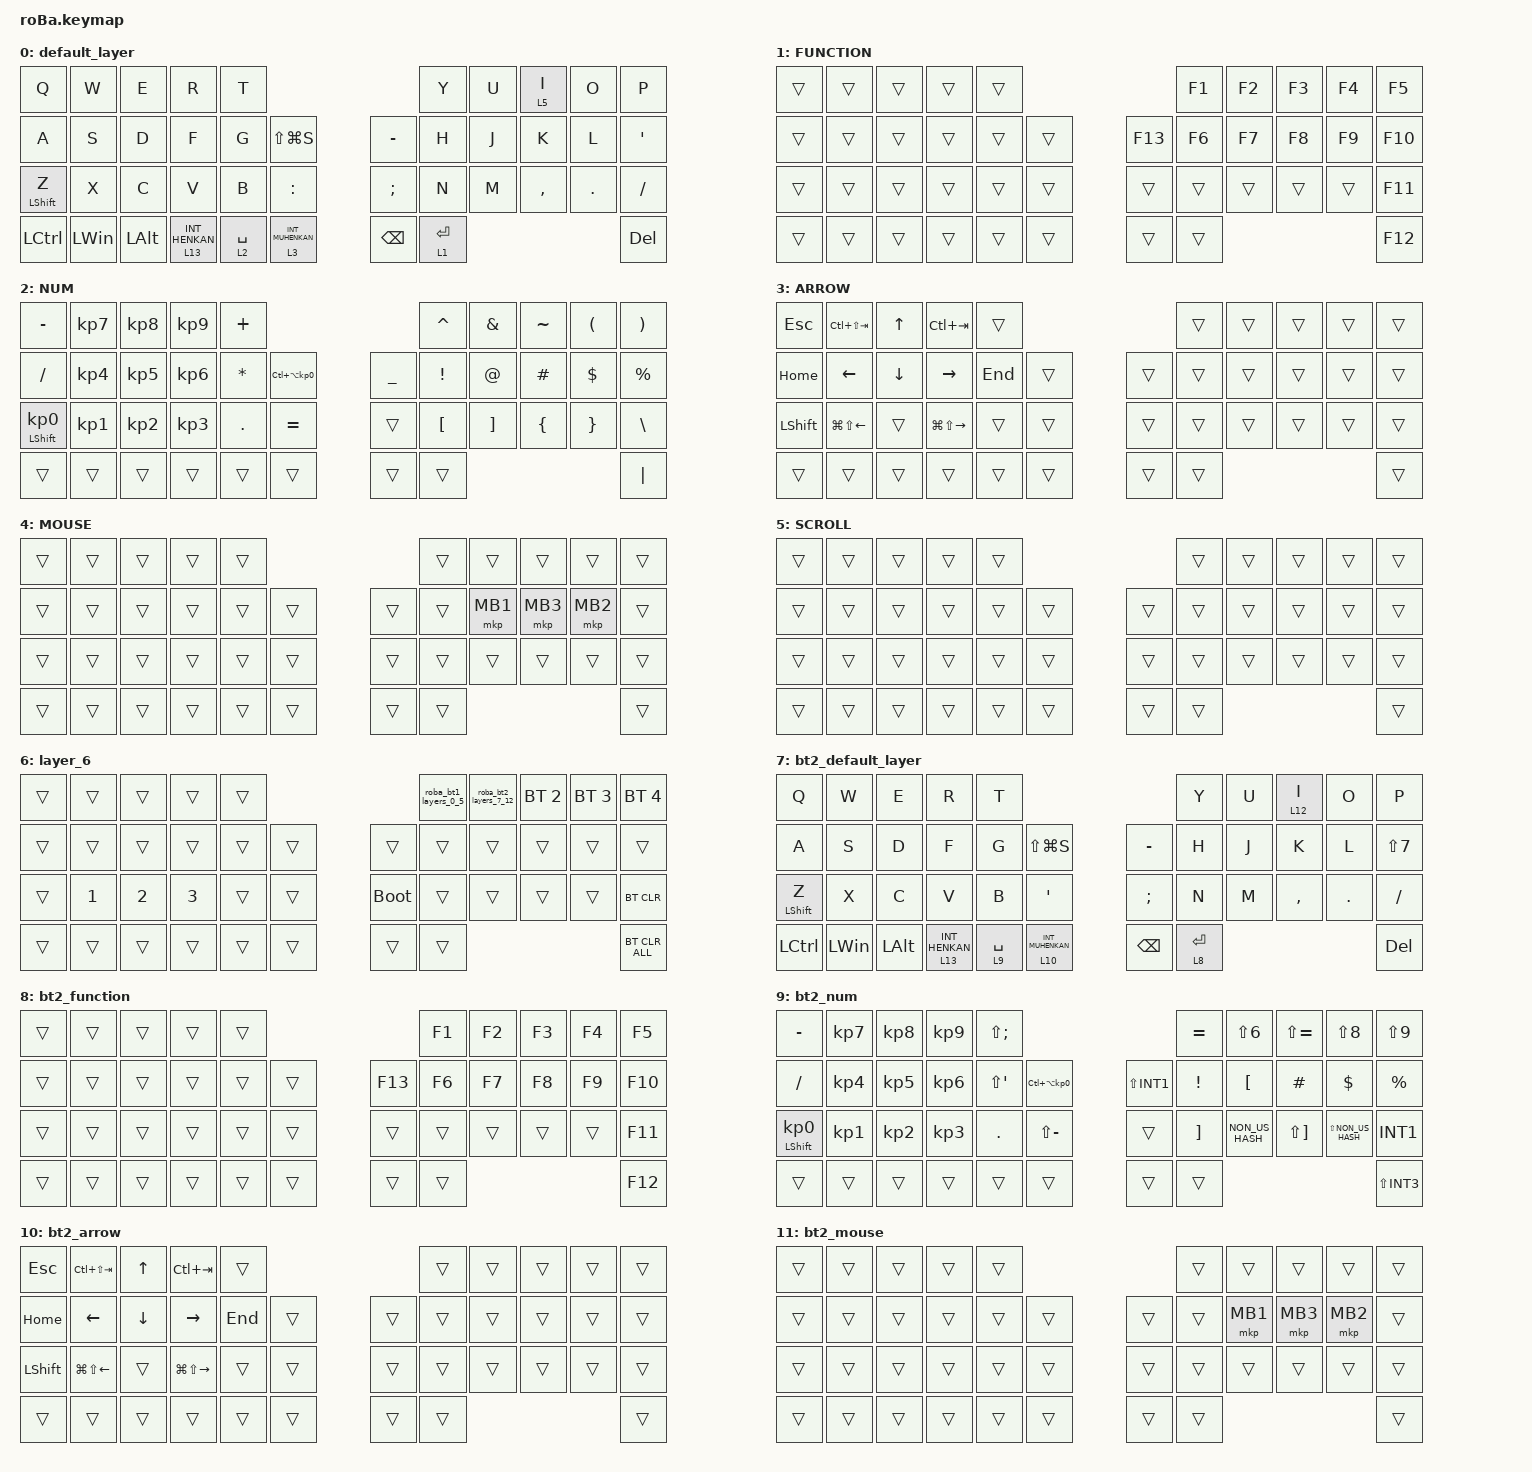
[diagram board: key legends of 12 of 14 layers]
#define ZMK_POINTING_DEFAULT_SCRL_VAL 80

#include <behaviors.dtsi>
#include <dt-bindings/zmk/bt.h>
#include <dt-bindings/zmk/keys.h>
#include <dt-bindings/zmk/pointing.h>

&mt {
    flavor = "balanced";
    quick-tap-ms = <0>;
};

&trackball {
    automouse-layer = <11>;
    scroll-layers = <12>;

    // arrows {
    //     layers = <3>;
    //     bindings =
    //         <&kp RIGHT_ARROW>,
    //         <&kp LEFT_ARROW>,
    //         <&kp UP_ARROW>,
    //         <&kp DOWN_ARROW>;

    //     tick = <10>;
    //     wait-ms = <5>;
    //     tap-ms = <5>;
    // };
};

/ {
    combos {
        compatible = "zmk,combos";

        tab {
            bindings = <&kp TAB>;
            key-positions = <11 12>;
        };

        shift_tab {
            bindings = <&kp LS(TAB)>;
            key-positions = <12 13>;
        };

        muhennkann {
            bindings = <&to_layer_0 INT_MUHENKAN>;
            key-positions = <11 10>;
        };

        double_quotation {
            bindings = <&kp DOUBLE_QUOTES>;
            key-positions = <20 21>;
        };

        eq {
            bindings = <&kp EQUAL>;
            key-positions = <24 25>;
        };
    };

    macros {
        roba_bt1_layers_0_5: roba_bt1_layers_0_5 {
            compatible = "zmk,behavior-macro";
            #binding-cells = <0>;
            display-name = "BT1 Layer Set 0";
            bindings = <&macro_tap &bt BT_SEL 0>, <&macro_tap &to 0>;
        };

        roba_bt2_layers_7_12: roba_bt2_layers_7_12 {
            compatible = "zmk,behavior-macro";
            #binding-cells = <0>;
            display-name = "BT2 Layer Set 7";
            bindings = <&macro_tap &bt BT_SEL 1>, <&macro_tap &to 7>;
        };

        to_layer_0: to_layer_0 {
            compatible = "zmk,behavior-macro-one-param";
            #binding-cells = <1>;
            bindings = <&to 0 &macro_param_1to1 &kp MACRO_PLACEHOLDER>;
            label = "TO_LAYER_0";
        };

        to_layer_7: to_layer_7 {
            compatible = "zmk,behavior-macro-one-param";
            #binding-cells = <1>;
            bindings = <&to 7 &macro_param_1to1 &kp MACRO_PLACEHOLDER>;
            label = "TO_LAYER_7";
        };
    };

    behaviors {
        encoder_msc_down_up: encoder_msc_down_up {
            compatible = "zmk,behavior-sensor-rotate";
            label = "ENCODER_MSC_DOWN_UP";
            #sensor-binding-cells = <0>;
            bindings = <&msc SCRL_DOWN>, <&msc SCRL_UP>;
            tap-ms = <20>;
        };

        lt_to_layer_0: lt_to_layer_0 {
            compatible = "zmk,behavior-hold-tap";
            label = "LAYER_TAP_TO_0";
            bindings = <&mo>, <&to_layer_0>;

            #binding-cells = <2>;
            tapping-term-ms = <200>;
        };

        lt_to_layer_7: lt_to_layer_7 {
            compatible = "zmk,behavior-hold-tap";
            label = "LAYER_TAP_TO_7";
            bindings = <&mo>, <&to_layer_7>;

            #binding-cells = <2>;
            tapping-term-ms = <200>;
        };
    };

    keymap {
        compatible = "zmk,keymap";

        default_layer {
            bindings = <
&kp Q             &kp W         &kp E         &kp R                        &kp T                                                          &kp Y        &kp U  &lt 5 I    &kp O    &kp P
&kp A             &kp S         &kp D         &kp F                        &kp G        &kp LS(LG(S))                      &kp MINUS      &kp H        &kp J  &kp K      &kp L    &kp SQT
&mt LEFT_SHIFT Z  &kp X         &kp C         &kp V                        &kp B        &kp COLON                          &kp SEMICOLON  &kp N        &kp M  &kp COMMA  &kp DOT  &kp SLASH
&kp LCTRL         &kp LEFT_WIN  &kp LEFT_ALT  &lt_to_layer_0 13 INT_HENKAN  &lt 2 SPACE  &lt_to_layer_0 3 INT_MUHENKAN      &kp BACKSPACE  &lt 1 ENTER                             &kp DEL
            >;

            sensor-bindings = <&encoder_msc_down_up>;
        };

        FUNCTION {
            bindings = <
&trans  &trans  &trans  &trans  &trans                       &kp F1  &kp F2  &kp F3  &kp F4  &kp F5
&trans  &trans  &trans  &trans  &trans  &trans      &kp F13  &kp F6  &kp F7  &kp F8  &kp F9  &kp F10
&trans  &trans  &trans  &trans  &trans  &trans      &trans   &trans  &trans  &trans  &trans  &kp F11
&trans  &trans  &trans  &trans  &trans  &trans      &trans   &trans                          &kp F12
            >;
        };

        NUM {
            bindings = <
&kp MINUS                   &kp KP_NUMBER_7  &kp KP_NUMBER_8  &kp KP_NUMBER_9  &kp PLUS                                                   &kp CARET         &kp AMPERSAND      &kp TILDE       &kp LEFT_PARENTHESIS  &kp RIGHT_PARENTHESIS
&kp SLASH                   &kp KP_NUMBER_4  &kp KP_NUMBER_5  &kp KP_NUMBER_6  &kp ASTERISK  &kp LC(LA(KP_NUMBER_0))      &kp UNDERSCORE  &kp EXCLAMATION   &kp AT_SIGN        &kp HASH        &kp DOLLAR            &kp PERCENT
&mt LEFT_SHIFT KP_NUMBER_0  &kp KP_NUMBER_1  &kp KP_NUMBER_2  &kp KP_NUMBER_3  &kp PERIOD    &kp EQUAL                    &trans          &kp LEFT_BRACKET  &kp RIGHT_BRACKET  &kp LEFT_BRACE  &kp RIGHT_BRACE       &kp BACKSLASH
&trans                      &trans           &trans           &trans           &trans        &trans                       &trans          &trans                                                                     &kp PIPE
            >;
        };

        ARROW {
            bindings = <
&kp ESCAPE      &kp LC(LS(TAB))         &kp UP_ARROW    &kp LC(TAB)              &trans                       &trans  &trans  &trans  &trans  &trans
&kp HOME        &kp LEFT_ARROW          &kp DOWN_ARROW  &kp RIGHT_ARROW          &kp END  &trans      &trans  &trans  &trans  &trans  &trans  &trans
&kp LEFT_SHIFT  &kp LG(LS(LEFT_ARROW))  &trans          &kp LG(LS(RIGHT_ARROW))  &trans   &trans      &trans  &trans  &trans  &trans  &trans  &trans
&trans          &trans                  &trans          &trans                   &trans   &trans      &trans  &trans                          &trans
            >;

            sensor-bindings = <&inc_dec_kp LC(PAGE_UP) LC(PAGE_DOWN)>;
        };

        MOUSE {
            bindings = <
&trans  &trans  &trans  &trans  &trans                      &trans  &trans    &trans    &trans    &trans
&trans  &trans  &trans  &trans  &trans  &trans      &trans  &trans  &mkp MB1  &mkp MB3  &mkp MB2  &trans
&trans  &trans  &trans  &trans  &trans  &trans      &trans  &trans  &trans    &trans    &trans    &trans
&trans  &trans  &trans  &trans  &trans  &trans      &trans  &trans                                &trans
            >;
        };

        SCROLL {
            bindings = <
&trans  &trans  &trans  &trans  &trans                      &trans  &trans  &trans  &trans  &trans
&trans  &trans  &trans  &trans  &trans  &trans      &trans  &trans  &trans  &trans  &trans  &trans
&trans  &trans  &trans  &trans  &trans  &trans      &trans  &trans  &trans  &trans  &trans  &trans
&trans  &trans  &trans  &trans  &trans  &trans      &trans  &trans                          &trans
            >;
        };

        layer_6 {
            bindings = <
&trans  &trans        &trans        &trans        &trans                           &roba_bt1_layers_0_5  &roba_bt2_layers_7_12  &bt BT_SEL 2  &bt BT_SEL 3  &bt BT_SEL 4
&trans  &trans        &trans        &trans        &trans  &trans      &trans       &trans        &trans        &trans        &trans        &trans
&trans  &kp NUMBER_1  &kp NUMBER_2  &kp NUMBER_3  &trans  &trans      &bootloader  &trans        &trans        &trans        &trans        &bt BT_CLR
&trans  &trans        &trans        &trans        &trans  &trans      &trans       &trans                                                  &bt BT_CLR_ALL
            >;
        };

        bt2_default_layer {
            bindings = <
&kp Q             &kp W         &kp E         &kp R                         &kp T                                                          &kp Y        &kp U  &lt 12 I   &kp O    &kp P
&kp A             &kp S         &kp D         &kp F                         &kp G        &kp LS(LG(S))                      &kp MINUS      &kp H        &kp J  &kp K      &kp L    &kp LS(NUMBER_7)
&mt LEFT_SHIFT Z  &kp X         &kp C         &kp V                         &kp B        &kp SINGLE_QUOTE                   &kp SEMICOLON  &kp N        &kp M  &kp COMMA  &kp DOT  &kp SLASH
&kp LCTRL         &kp LEFT_WIN  &kp LEFT_ALT  &lt_to_layer_7 13 INT_HENKAN  &lt 9 SPACE  &lt_to_layer_7 10 INT_MUHENKAN      &kp BACKSPACE  &lt 8 ENTER                             &kp DEL
            >;

            sensor-bindings = <&encoder_msc_down_up>;
        };

        bt2_function {
            bindings = <
&trans  &trans  &trans  &trans  &trans                       &kp F1  &kp F2  &kp F3  &kp F4  &kp F5
&trans  &trans  &trans  &trans  &trans  &trans      &kp F13  &kp F6  &kp F7  &kp F8  &kp F9  &kp F10
&trans  &trans  &trans  &trans  &trans  &trans      &trans   &trans  &trans  &trans  &trans  &kp F11
&trans  &trans  &trans  &trans  &trans  &trans      &trans   &trans                          &kp F12
            >;
        };

        bt2_num {
            bindings = <
&kp MINUS                   &kp KP_NUMBER_7  &kp KP_NUMBER_8  &kp KP_NUMBER_9  &kp LS(SEMICOLON)                                      &kp EQUAL           &kp LS(NUMBER_6)     &kp LS(EQUAL)       &kp LS(NUMBER_8)  &kp LS(NUMBER_9)
&kp SLASH                   &kp KP_NUMBER_4  &kp KP_NUMBER_5  &kp KP_NUMBER_6  &kp LS(SINGLE_QUOTE)  &kp LC(LA(KP_NUMBER_0))      &kp LS(INT1)     &kp EXCLAMATION     &kp LEFT_BRACKET  &kp HASH        &kp DOLLAR        &kp PERCENT
&mt LEFT_SHIFT KP_NUMBER_0  &kp KP_NUMBER_1  &kp KP_NUMBER_2  &kp KP_NUMBER_3  &kp PERIOD            &kp LS(MINUS)               &trans           &kp RIGHT_BRACKET  &kp NON_US_HASH   &kp LS(RIGHT_BRACKET)  &kp LS(NON_US_HASH)  &kp INT1
&trans                      &trans           &trans           &trans           &trans                &trans                      &trans           &trans                                                                       &kp LS(INT3)
            >;
        };

        bt2_arrow {
            bindings = <
&kp ESCAPE      &kp LC(LS(TAB))         &kp UP_ARROW    &kp LC(TAB)              &trans                       &trans  &trans  &trans  &trans  &trans
&kp HOME        &kp LEFT_ARROW          &kp DOWN_ARROW  &kp RIGHT_ARROW          &kp END  &trans      &trans  &trans  &trans  &trans  &trans  &trans
&kp LEFT_SHIFT  &kp LG(LS(LEFT_ARROW))  &trans          &kp LG(LS(RIGHT_ARROW))  &trans   &trans      &trans  &trans  &trans  &trans  &trans  &trans
&trans          &trans                  &trans          &trans                   &trans   &trans      &trans  &trans                          &trans
            >;

            sensor-bindings = <&inc_dec_kp LC(PAGE_UP) LC(PAGE_DOWN)>;
        };

        bt2_mouse {
            bindings = <
&trans  &trans  &trans  &trans  &trans                      &trans  &trans    &trans    &trans    &trans
&trans  &trans  &trans  &trans  &trans  &trans      &trans  &trans  &mkp MB1  &mkp MB3  &mkp MB2  &trans
&trans  &trans  &trans  &trans  &trans  &trans      &trans  &trans  &trans    &trans    &trans    &trans
&trans  &trans  &trans  &trans  &trans  &trans      &trans  &trans                                &trans
            >;
        };

        bt2_scroll {
            bindings = <
&trans  &trans  &trans  &trans  &trans                      &trans  &trans  &trans  &trans  &trans
&trans  &trans  &trans  &trans  &trans  &trans      &trans  &trans  &trans  &trans  &trans  &trans
&trans  &trans  &trans  &trans  &trans  &trans      &trans  &trans  &trans  &trans  &trans  &trans
&trans  &trans  &trans  &trans  &trans  &trans      &trans  &trans                          &trans
            >;
        };

        connection_layer {
            bindings = <
&trans  &trans        &trans        &trans        &trans                           &roba_bt1_layers_0_5  &roba_bt2_layers_7_12  &bt BT_SEL 2  &bt BT_SEL 3  &bt BT_SEL 4
&trans  &trans        &trans        &trans        &trans  &trans      &trans       &trans        &trans        &trans        &trans        &trans
&trans  &kp NUMBER_1  &kp NUMBER_2  &kp NUMBER_3  &trans  &trans      &bootloader  &trans        &trans        &trans        &trans        &bt BT_CLR
&trans  &trans        &trans        &trans        &trans  &trans      &trans       &trans                                                  &bt BT_CLR_ALL
            >;
        };
    };
};
